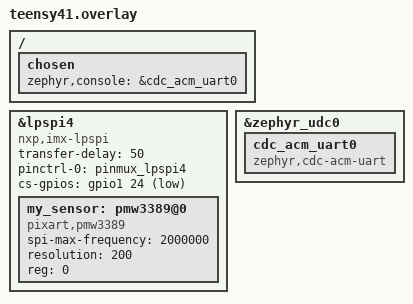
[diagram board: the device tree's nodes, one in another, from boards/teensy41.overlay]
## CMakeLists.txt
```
# SPDX-License-Identifier: Apache-2.0

cmake_minimum_required(VERSION 3.20.0)

set(BOARD teensy41)

get_filename_component(PMW3389_MODULE
    "${CMAKE_CURRENT_LIST_DIR}/../../../../../modules/pmw3389"
    ABSOLUTE
)
get_filename_component(LPSPI_MODULE
    "${CMAKE_CURRENT_LIST_DIR}/../../../../../modules/lpspi"
    ABSOLUTE
)

list(APPEND EXTRA_ZEPHYR_MODULES 
	${PMW3389_MODULE}
	${LPSPI_MODULE}
)

find_package(Zephyr REQUIRED HINTS $ENV{ZEPHYR_BASE})
project(pmw3389_sample)

FILE(GLOB app_sources src/*.cpp)
target_sources(app PRIVATE ${app_sources})
```

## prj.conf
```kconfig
# Enable C++ and STL support 
CONFIG_CPP=y 
CONFIG_CPP_EXCEPTIONS=y 
CONFIG_CPP_RTTI=y 
CONFIG_STD_CPP23=y 
CONFIG_GLIBCXX_LIBCPP=y 
CONFIG_NEWLIB_LIBC=y 
CONFIG_NEWLIB_LIBC_NANO=n 

# System 
CONFIG_FPU=y 
CONFIG_FPU_SHARING=y 
CONFIG_THREAD_ANALYZER=y

# USB (new)
CONFIG_USB_DEVICE_STACK_NEXT=y
CONFIG_CDC_ACM_SERIAL_INITIALIZE_AT_BOOT=y

# Enable logging
CONFIG_LOG=y
CONFIG_SENSOR_LOG_LEVEL_WRN=y
CONFIG_USBD_LOG_LEVEL_WRN=y
CONFIG_LOG_BUFFER_SIZE=8192
# Enable console
CONFIG_CONSOLE=y
CONFIG_UART_CONSOLE=y
CONFIG_LOG_PRINTK=n
CONFIG_SHELL_LOG_BACKEND=n

CONFIG_SENSOR=y
CONFIG_SPI=y
CONFIG_PMW3389=y
```

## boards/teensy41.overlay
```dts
&lpspi4 {
    // driver: zephyr 4.3.0-rc1
    // compatible = "nxp,lpspi";
    // driver: zephyr 4.0.0
    compatible = "nxp,imx-lpspi";

    status = "okay";

    transfer-delay = <50>; // ns

    pinctrl-0 = <&pinmux_lpspi4>;
    pinctrl-names = "default";
    
    cs-gpios = <&gpio1 24 GPIO_ACTIVE_LOW>; // Steering 1 (front-left)

    my_sensor: pmw3389@0 {
        compatible = "pixart,pmw3389";
        spi-max-frequency = <2000000>; // 2MHz
        resolution = <200>; // overflow in 0.5s at 8m/s -> 200 CPI
        status = "okay";
        reg = <0>;
    };

};

&zephyr_udc0 {
    cdc_acm_uart0: cdc_acm_uart0 {
		compatible = "zephyr,cdc-acm-uart";
	};
};

/ {
    chosen {
	    zephyr,console = &cdc_acm_uart0;
        // use hardware uart for early debug (if necessary):
        // zephyr,console = &lpuart6;
    };
};
```

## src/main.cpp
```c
#include <zephyr/device.h>
#include <zephyr/drivers/sensor.h>
#include <pmw3389.h>

int main(){
    printk("AS5x47 sample application\n");

    const device *my_sensor = DEVICE_DT_GET(DT_NODELABEL(my_sensor));

    if (!device_is_ready(my_sensor)) {
		printk("my_sensor: device not ready.\n");
		return 0;
	}

    while (true) {        
        sensor_sample_fetch(my_sensor);
        sensor_value v_x{}, v_y{};
        sensor_channel_get(my_sensor,
                           (sensor_channel) sensor_channel_pmw3389::SENSOR_CHAN_PMW3389_DISTANCE_X,
                           &v_x);
        sensor_channel_get(my_sensor,
                           (sensor_channel) sensor_channel_pmw3389::SENSOR_CHAN_PMW3389_DISTANCE_Y,
                           &v_y);
        printk("DELTA_X: %f, DELTA_Y: %f", sensor_value_to_double(&v_x), sensor_value_to_double(&v_y));
    }
}
```
